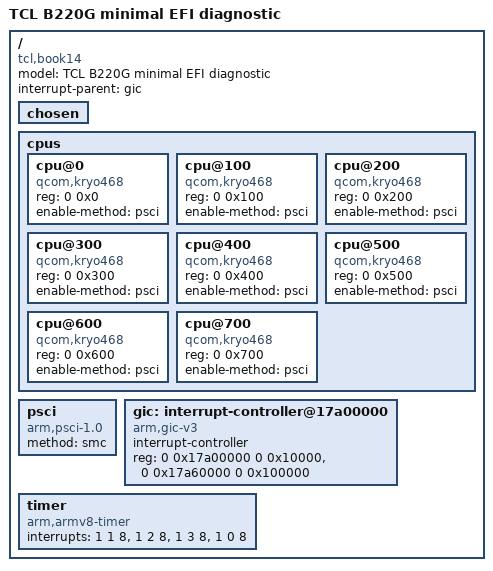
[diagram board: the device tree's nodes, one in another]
// Experimental minimal EFI diagnostic tree, not a complete TCL board description.
/dts-v1/;
/ {
    model = "TCL B220G minimal EFI diagnostic";
    compatible = "tcl,book14", "qcom,sc7180";
    #address-cells = <2>;
    #size-cells = <2>;
    interrupt-parent = <&gic>;
    chosen {};
    cpus {
        #address-cells = <2>;
        #size-cells = <0>;
        cpu@0 { device_type = "cpu"; compatible = "qcom,kryo468"; reg = <0 0x0>; enable-method = "psci"; };
        cpu@100 { device_type = "cpu"; compatible = "qcom,kryo468"; reg = <0 0x100>; enable-method = "psci"; };
        cpu@200 { device_type = "cpu"; compatible = "qcom,kryo468"; reg = <0 0x200>; enable-method = "psci"; };
        cpu@300 { device_type = "cpu"; compatible = "qcom,kryo468"; reg = <0 0x300>; enable-method = "psci"; };
        cpu@400 { device_type = "cpu"; compatible = "qcom,kryo468"; reg = <0 0x400>; enable-method = "psci"; };
        cpu@500 { device_type = "cpu"; compatible = "qcom,kryo468"; reg = <0 0x500>; enable-method = "psci"; };
        cpu@600 { device_type = "cpu"; compatible = "qcom,kryo468"; reg = <0 0x600>; enable-method = "psci"; };
        cpu@700 { device_type = "cpu"; compatible = "qcom,kryo468"; reg = <0 0x700>; enable-method = "psci"; };
    };
    psci { compatible = "arm,psci-1.0", "arm,psci-0.2"; method = "smc"; };
    gic: interrupt-controller@17a00000 {
        compatible = "arm,gic-v3";
        #interrupt-cells = <3>;
        #address-cells = <2>;
        #size-cells = <2>;
        ranges;
        interrupt-controller;
        reg = <0 0x17a00000 0 0x10000>, <0 0x17a60000 0 0x100000>;
    };
    // PPI numbers match GTDT. Polarity follows Linux sc7180.dtsi;
    // GTDT reports high rather than low. See README for the discrepancy.
    timer {
        compatible = "arm,armv8-timer";
        interrupts = <1 1 8>, <1 2 8>, <1 3 8>, <1 0 8>;
    };
    // RAM and framebuffer are obtained via EFI; no guessed MMIO or memory size.
};
